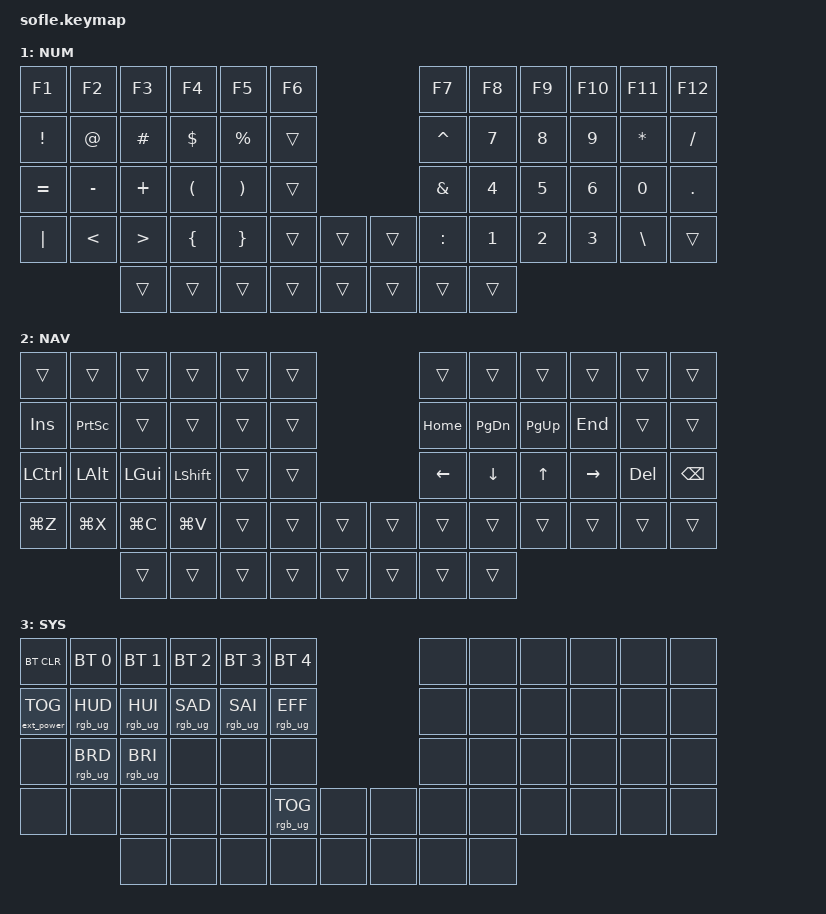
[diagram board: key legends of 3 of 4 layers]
/*
 * Copyright (c) 2020 The ZMK Contributors
 * SPDX-License-Identifier: MIT
 */

#include <behaviors.dtsi>
#include <dt-bindings/zmk/keys.h>
#include <dt-bindings/zmk/bt.h>
#include <dt-bindings/zmk/rgb.h>
#include <dt-bindings/zmk/ext_power.h>

#define BASE 0
#define LOWER 1
#define RAISE 2
#define ADJUST 3

/ {
    behaviors {
        // Home row mods для Mac (Cmd важнее Ctrl!)
        hm: homerow_mods {
            compatible = "zmk,behavior-hold-tap";
            #binding-cells = <2>;
            tapping-term-ms = <200>;
            quick-tap-ms = <175>;
            require-prior-idle-ms = <150>;
            flavor = "balanced";
            bindings = <&kp>, <&kp>;
        };
        
        lt: layer_tap {
            compatible = "zmk,behavior-hold-tap";
            #binding-cells = <2>;
            tapping-term-ms = <200>;
            quick-tap-ms = <175>;
            flavor = "balanced";
            bindings = <&mo>, <&kp>;
        };
    };

    combos {
        compatible = "zmk,combos";
        
        // ESC на Q+W
        combo_esc {
            timeout-ms = <50>;
            key-positions = <13 14>;
            bindings = <&kp ESC>;
        };
        
        // Tab на W+E
        combo_tab {
            timeout-ms = <50>;
            key-positions = <14 15>;
            bindings = <&kp TAB>;
        };
        
        // Backspace на O+P
        combo_bspc {
            timeout-ms = <50>;
            key-positions = <21 22>;
            bindings = <&kp BSPC>;
        };
        
        // Delete на P+[
        combo_del {
            timeout-ms = <50>;
            key-positions = <22 23>;
            bindings = <&kp DEL>;
        };
        
        // Enter на L+;
        combo_enter {
            timeout-ms = <50>;
            key-positions = <33 34>;
            bindings = <&kp ENTER>;
        };
        
        // Spotlight (Cmd+Space) на D+F
        combo_spotlight {
            timeout-ms = <50>;
            key-positions = <27 28>;
            bindings = <&kp LG(SPACE)>;
        };
        
        // Alfred/Raycast (Opt+Space) на S+D
        combo_alfred {
            timeout-ms = <50>;
            key-positions = <26 27>;
            bindings = <&kp LA(SPACE)>;
        };
        
        // Screenshot (Cmd+Shift+4) на J+K
        combo_screenshot {
            timeout-ms = <50>;
            key-positions = <31 32>;
            bindings = <&kp LG(LS(N4))>;
        };
    };

    conditional_layers {
        compatible = "zmk,conditional-layers";
        adjust_layer {
            if-layers = <LOWER RAISE>;
            then-layer = <ADJUST>;
        };
    };

    keymap {
        compatible = "zmk,keymap";

        base_layer {
            display-name = "BASE";
// ╭──────────────────────────────────────────────────────╮   ╭──────────────────────────────────────────────────────╮
// │   `      1      2      3      4      5               │   │         6      7      8      9      0      -         │
// │   Q      W      E      R      T      ESC             │   │   BSPC  Y      U      I      O      P      [         │
// │   A      S      D      F      G      TAB             │   │   ENTER H      J      K      L      ;      '         │
// │   Z      X      C      V      B      MUTE   │   │LANG│         N      M      ,      .      /      ]         │
// ╰────────── OPT  CMD/LOWER  CTRL/SPC  SHFT/ENT│   │SPC/SHFT BSPC/RAISE  CMD  OPT ──────────╯
            bindings = <
&kp GRAVE    &kp N1       &kp N2           &kp N3            &kp N4             &kp N5                                        &kp N6             &kp N7            &kp N8             &kp N9        &kp N0     &kp MINUS
&kp Q        &kp W        &kp E            &kp R             &kp T              &kp ESC                                       &kp BSPC           &kp Y             &kp U              &kp I         &kp O      &kp P      &kp LBKT
&hm LCTRL A  &hm LALT S   &hm LGUI D       &hm LSHFT F       &kp G              &kp TAB                                       &kp ENTER          &kp H             &hm RSHFT J        &hm RGUI K    &hm RALT L &hm RCTRL SEMI &kp SQT
&kp Z        &kp X        &kp C            &kp V             &kp B              &kp C_MUTE     &kp LG(SPACE)                  &kp N              &kp M             &kp COMMA          &kp DOT       &kp FSLH   &kp RBKT
                          &kp LALT         &lt LOWER LGUI    &hm LCTRL SPACE    &hm LSHFT RET  &hm RSHFT SPACE  &lt RAISE BSPC &kp RGUI          &kp RALT
            >;

            sensor-bindings = <&inc_dec_kp C_VOL_UP C_VOL_DN &inc_dec_kp PG_UP PG_DN>;
        };

        lower_layer {
            display-name = "NUM";
// ╭──────────────────────────────────────────────────────╮   ╭──────────────────────────────────────────────────────╮
// │   F1     F2     F3     F4     F5     F6              │   │         F7     F8     F9    F10    F11    F12        │
// │   !      @      #      $      %                      │   │         ^      7      8      9      *      /         │
// │   =      -      +      (      )                      │   │         &      4      5      6      0      .         │
// │   |      <      >      {      }             │   │   │         :      1      2      3      \                 │
// ╰────────────────────────────────────────     │   │   │                                    ──────────────────╯
            bindings = <
&kp F1       &kp F2       &kp F3       &kp F4       &kp F5       &kp F6                            &kp F7       &kp F8       &kp F9       &kp F10      &kp F11      &kp F12
&kp EXCL     &kp AT       &kp HASH     &kp DLLR     &kp PRCNT    &trans                            &kp CARET    &kp N7       &kp N8       &kp N9       &kp ASTRK    &kp FSLH
&kp EQUAL    &kp MINUS    &kp PLUS     &kp LPAR     &kp RPAR     &trans                            &kp AMPS     &kp N4       &kp N5       &kp N6       &kp N0       &kp DOT
&kp PIPE     &kp LT       &kp GT       &kp LBRC     &kp RBRC     &trans       &trans    &trans     &kp COLON    &kp N1       &kp N2       &kp N3       &kp BSLH     &trans
                          &trans       &trans       &trans       &trans       &trans    &trans     &trans       &trans
            >;

            sensor-bindings = <&inc_dec_kp C_VOL_UP C_VOL_DN &inc_dec_kp C_BRI_UP C_BRI_DN>;
        };

        raise_layer {
            display-name = "NAV";
// ╭──────────────────────────────────────────────────────╮   ╭──────────────────────────────────────────────────────╮
// │                                                       │   │                                                       │
// │  INS   PSCR                                          │   │  HOME  PGDN  PGUP   END                              │
// │ CTRL   OPT   CMD   SHFT                              │   │   ←     ↓     ↑     →    DEL   BSPC                  │
// │ UNDO   CUT   COPY  PASTE                    │   │   │                                                       │
// ╰──────────────────────────────────           │   │   │                         ──────────────────────────────╯
            bindings = <
&trans       &trans       &trans       &trans       &trans       &trans                            &trans       &trans       &trans       &trans       &trans       &trans
&kp INS      &kp PSCRN    &trans       &trans       &trans       &trans                            &kp HOME     &kp PG_DN    &kp PG_UP    &kp END      &trans       &trans
&kp LCTRL    &kp LALT     &kp LGUI     &kp LSHFT    &trans       &trans                            &kp LEFT     &kp DOWN     &kp UP       &kp RIGHT    &kp DEL      &kp BSPC
&kp LG(Z)    &kp LG(X)    &kp LG(C)    &kp LG(V)    &trans       &trans       &trans    &trans     &trans       &trans       &trans       &trans       &trans       &trans
                          &trans       &trans       &trans       &trans       &trans    &trans     &trans       &trans
            >;

            sensor-bindings = <&inc_dec_kp C_VOL_UP C_VOL_DN &inc_dec_kp LEFT RIGHT>;
        };

        adjust_layer {
            display-name = "SYS";
// ╭──────────────────────────────────────────────────────╮   ╭──────────────────────────────────────────────────────╮
// │ BTCLR  BT1   BT2   BT3   BT4   BT5                   │   │                                                       │
// │ EXTPW  HUD   HUI   SAD   SAI   EFF                   │   │                                                       │
// │        BRD   BRI                                     │   │                                                       │
// │                                        TOG   │   │   │                                                       │
// ╰──────────────────────────────────           │   │   │                         ──────────────────────────────╯
            bindings = <
&bt BT_CLR        &bt BT_SEL 0     &bt BT_SEL 1     &bt BT_SEL 2     &bt BT_SEL 3     &bt BT_SEL 4                       &none  &none  &none  &none  &none  &none
&ext_power EP_TOG &rgb_ug RGB_HUD  &rgb_ug RGB_HUI  &rgb_ug RGB_SAD  &rgb_ug RGB_SAI  &rgb_ug RGB_EFF                    &none  &none  &none  &none  &none  &none
&none             &rgb_ug RGB_BRD  &rgb_ug RGB_BRI  &none            &none            &none                              &none  &none  &none  &none  &none  &none
&none             &none            &none            &none            &none            &rgb_ug RGB_TOG  &none    &none    &none  &none  &none  &none  &none  &none
                                   &none            &none            &none            &none            &none    &none    &none  &none
            >;
        };
    };
};
